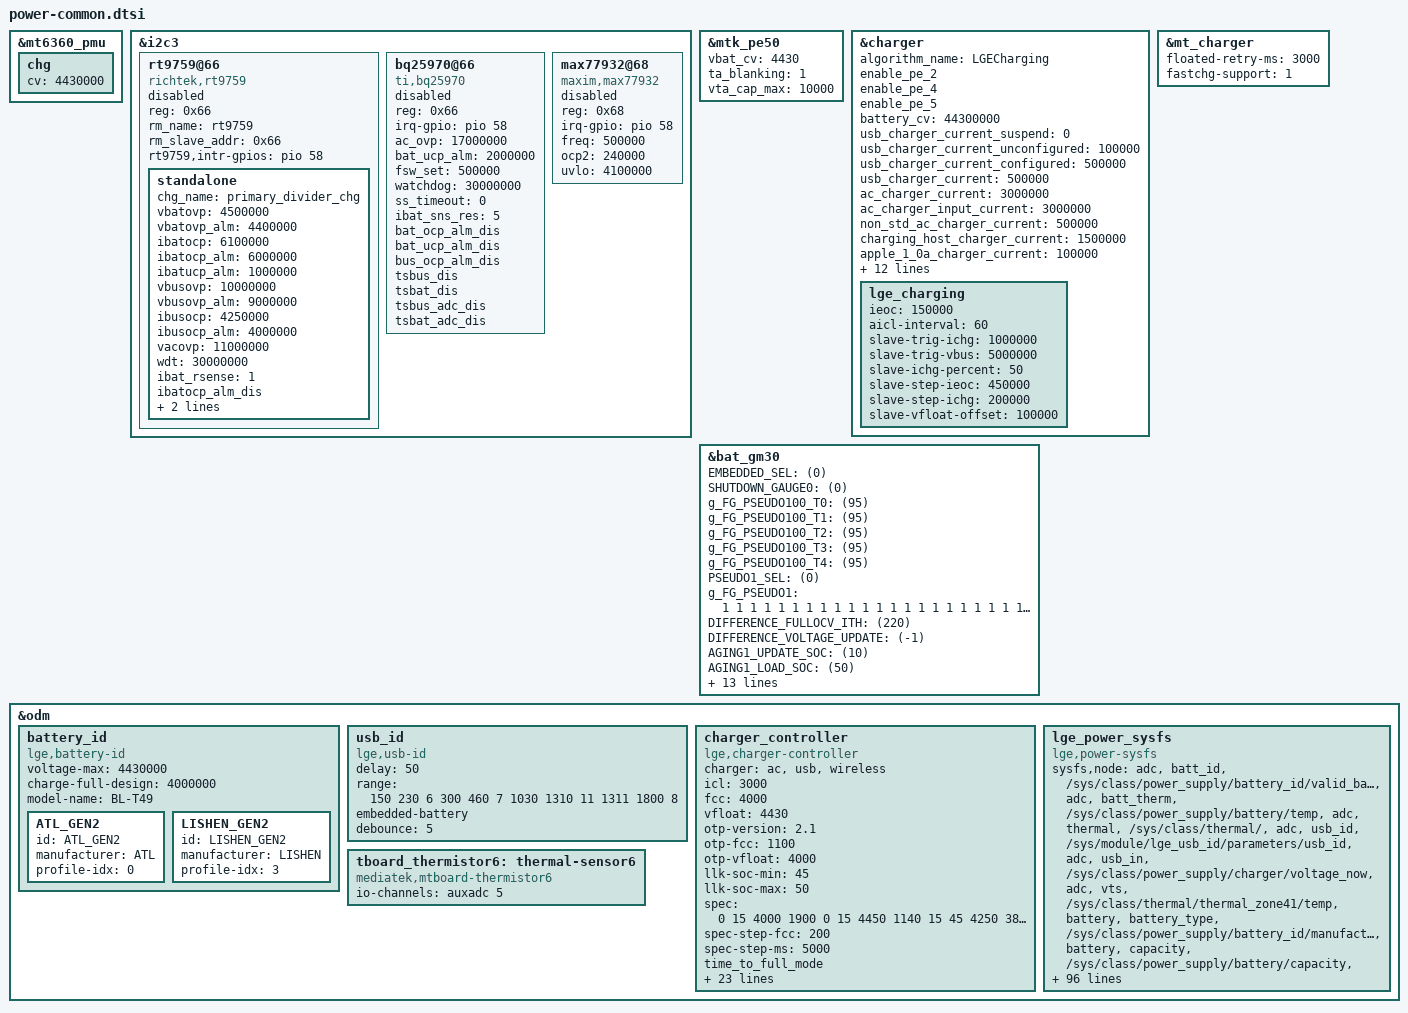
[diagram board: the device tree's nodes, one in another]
/*
 * Mediatek's mt6885 SoC device tree source
 *
 * Copyright (C) 2016 MediaTek Inc.
 *
 * This program is free software; you can redistribute it and/or modify
 * it under the terms of the GNU General Public License version 2 as
 * published by the Free Software Foundation.
 *
 * This program is distributed in the hope that it will be useful,
 * but WITHOUT ANY WARRANTY; without even the implied warranty of
 * MERCHANTABILITY or FITNESS FOR A PARTICULAR PURPOSE.
 * See http://www.gnu.org/licenses/gpl-2.0.html for more details.
 */

&mt6360_pmu {
	chg {
		cv = <4430000>;		/* uA */
	};
};

/* Cap Divider Charger */
&i2c3 {
	rt9759@66 {
		compatible = "richtek,rt9759";
		status = "disabled";
		reg = <0x66>;
		rm_name = "rt9759";
		rm_slave_addr = /bits/ 8 <0x66>;
		rt9759,intr-gpios = <&pio 58 0x0>;
		standalone {
			chg_name = "primary_divider_chg";
			vbatovp = <4500000>;
			vbatovp_alm = <4400000>;
			ibatocp = <6100000>;
			ibatocp_alm = <6000000>;
			ibatucp_alm = <1000000>;
			vbusovp = <10000000>;
			vbusovp_alm = <9000000>;
			ibusocp = <4250000>;
			ibusocp_alm = <4000000>;
			vacovp = <11000000>;
			wdt = <30000000>;
			ibat_rsense = <1>; /* 0: 2mohm, 1: 5mohm */
			ibatocp_alm_dis;
			ibatucp_alm_dis;
			ibusocp_alm_dis;
		};
	};
};

&i2c3 {
	bq25970@66 {
		compatible = "ti,bq25970";
		status = "disabled";
		reg = <0x66>;
		irq-gpio = <&pio 58 0x0>;
		ac_ovp = <17000000>;		/* 17 V */
		bat_ucp_alm = <2000000>;	/* 2 A */
		fsw_set = <500000>;		/* 500 kHz */
		watchdog = <30000000>;		/* 30 sec */
		ss_timeout = <0>;		/* disable */
		ibat_sns_res = <5>;		/* 5 ohm */
		bat_ocp_alm_dis;
		bat_ucp_alm_dis;
		bus_ocp_alm_dis;
		tsbus_dis;
		tsbat_dis;
		tsbus_adc_dis;
		tsbat_adc_dis;
	};
};

&i2c3 {
	max77932@68 {
		compatible = "maxim,max77932";
		status = "disabled";
		reg = <0x68>;
		irq-gpio = <&pio 58 0x0>;

		freq = <500000>;
		ocp2 = <240000>;
		uvlo = <4100000>;
	};
};

&mtk_pe50 {
	vbat_cv = <4430>;
	ta_blanking = <1>;
	vta_cap_max = <10000>;
};

&charger {
	algorithm_name = "LGECharging";
	enable_pe_2;
	enable_pe_4;
	enable_pe_5;

	/* common */
	battery_cv = <44300000>;

	/* charging current */
	usb_charger_current_suspend = <0>;
	usb_charger_current_unconfigured = <100000>;
	usb_charger_current_configured = <500000>;
	usb_charger_current = <500000>;
	ac_charger_current = <3000000>;
	ac_charger_input_current = <3000000>;
	non_std_ac_charger_current = <500000>;
	charging_host_charger_current = <1500000>;
	apple_1_0a_charger_current = <100000>;
	apple_2_1a_charger_current = <2100000>;
	ta_ac_charger_current = <3200000>;
	ta_ac_charger_input_current = <1800000>;
	pd_charger_current = <4000000>;

	/* PE 2.0 */
	pe20_ichg_level_threshold = <500000>; /* uA */
	ta_start_battery_soc = <0>;
	ta_stop_battery_soc = <97>;

	/* cable measurement impedance */
	vbat_cable_imp_threshold = <3000000>; /* uV */

	/* PD */
	pd_vbus_low_bound = <5000000>;
	pd_vbus_upper_bound = <9000000>;
	pd_ichg_level_threshold = <1000000>; /* uA */
	pd_stop_battery_soc = <80>;

	/* LGE Charging Algorithm */
	lge_charging {
		ieoc = <150000>;
		aicl-interval = <60>;

		/* slave charger */
		slave-trig-ichg = <1000000>;
		slave-trig-vbus = <5000000>;
		slave-ichg-percent = <50>;
		slave-step-ieoc = <450000>;
		slave-step-ichg = <200000>;
		slave-vfloat-offset = <100000>;
	};
};

&mt_charger {
	floated-retry-ms = <3000>; /* 3000 ms */
	fastchg-support = <1>;
};

&bat_gm30 {
	/*	Configures whether using embedded battery or not.*/
	EMBEDDED_SEL = <(0)>;
	/* SOC_ZERO_PERCENT shutdown_cond  1:enable , 0:disable */
	SHUTDOWN_GAUGE0 = <(0)>;

	/*      Pseudo 100% percentage at T0.*/
	g_FG_PSEUDO100_T0 = <(95)>;
	/*      Pseudo 100% percentage at T1.*/
	g_FG_PSEUDO100_T1 = <(95)>;
	/*      Pseudo 100% percentage at T2.*/
	g_FG_PSEUDO100_T2 = <(95)>;
	/*      Pseudo 100% percentage at T3.*/
	g_FG_PSEUDO100_T3 = <(95)>;
	/*      Pseudo 100% percentage at T4.*/
	g_FG_PSEUDO100_T4 = <(95)>;

	PSEUDO1_SEL = <(0)>;

	g_FG_PSEUDO1 = <1  1  1  1
			1  1  1  1
			1  1  1  1
			1  1  1  1
			1  1  1  1
			1  1  1  1
			1  1  1  1
			1  1  1  1
			1  1  1  1
			1  1  1  1>;

	DIFFERENCE_FULLOCV_ITH = <(220)>;
	DIFFERENCE_VOLTAGE_UPDATE = <(-1)>;
	AGING1_UPDATE_SOC = <(10)>;
	AGING1_LOAD_SOC = <(50)>;
	AGING_TEMP_DIFF = <(15)>;
	AGING_TEMP_LOW_LIMIT = <(15)>;
	AGING_TEMP_HIGH_LIMIT = <(45)>;
	ZCV_SUSPEND_TIME = <(9)>;
	SLEEP_CURRENT_AVG = <(500)>; /*0.1mA*/

	CAR_TUNE_VALUE = <(100)>;
	HWOCV_OLDOCV_DIFF_CHR = <(2000)>;
	SWOCV_OLDOCV_DIFF_CHR = <(2000)>;
	VIR_OLDOCV_DIFF_EMB = <(2000)>;
	VIR_OLDOCV_DIFF_EMB_LT = <(2000)>;

	POWER_ON_CAR_CHR = <(20)>;
	POWER_ON_CAR_NOCHR = <(-35)>;

	/*The ui_soc will keep 100% until SOC drop X percents after unplugged.*/
	KEEP_100_PERCENT = <(3)>;

#include <lge/battery_BL-T49.dtsi>
};

/* Battery ID */
&odm {
	battery_id {
		compatible = "lge,battery-id";

		voltage-max = <4430000>;
		charge-full-design = <4000000>;
		model-name = "BL-T49";

		ATL_GEN2 {
			id = "ATL_GEN2";
			manufacturer = "ATL";
			profile-idx = <0>;
		};
		LISHEN_GEN2 {
			id = "LISHEN_GEN2";
			manufacturer = "LISHEN";
			profile-idx = <3>;
		};
	};
};

/* USB ID */
&odm {
	usb_id {
		compatible = "lge,usb-id";

		delay = <50>;

		/*
		 * Pull-up : 1.8V 500k (20%)
		 * ID : 56k (20%), 130k (20%), 910k (20%)
		 */
		range = <
		/*	min 	max 	type	*/
			150	230	6	/* 6: LT_CABLE_56K */
			300	460	7	/* 7: LT_CABLE_130K */
			1030	1310	11	/* 11: LT_CABLE_910K */
			1311	1800	8	/* 8: USB_CABLE_400MA */
		>;

		embedded-battery;
		debounce = <5>;
	};
};

/* Charger Controller */
&odm {
	charger_controller {
		compatible = "lge,charger-controller";
		charger = "ac", "usb", "wireless";

		/* base information */
		icl = <3000>;
		fcc = <4000>;
		vfloat = <4430>;

		/* otp */
		otp-version = "2.1";
		otp-fcc = <1100>;
		otp-vfloat = <4000>;

		/* llk */
		llk-soc-min = <45>;
		llk-soc-max = <50>;

		/* spec */
		spec = <
			 0 15 4000 1900	/* 0.5C */
			 0 15 4450 1140	/* 0.3C */
			15 45 4250 3880	/* 1.0C */
			15 45 4450 2328	/* 0.6C */
			45 60 4410 1900	/* 0.5C */
		>;
		spec-step-fcc = <200>;
		spec-step-ms = <5000>;

		/* time to full */
		time_to_full_mode;
		battery_full_capacity = <4000>;
		sdp_current = <500>;
		dcp_current = <2000>;
		pep_current = <2800>;
		non_std_current = <500>;
		report_ttf_comp = <0>;
		sdp_comp = <3>;
		dcp_comp = <15>;
		cdp_comp = <15>;
		pep_comp = <2>;
		pd_comp = <2>;
		non_std_comp = <3>;
		min_comp = <0>;
		batt_comp = <
			0	/* LGC */
			0	/* TOCAD */
			(-3)	/* ATL */
			0	/* BYD */
			0	/* LISHEN */
		>;
		cc_data = <
			/* current soc */
			2000	0
		>;
		cv_data = <
			/* current soc time */
			1892	811	2296
			1858	816	2262
			1810	821	2227
			1769	826	2192
			1733	831	2155
			1690	836	2121
			1656	841	2083
			1612	846	2045
			1576	851	2007
			1535	856	1966
			1491	861	1923
			1455	866	1880
			1413	871	1837
			1376	876	1794
			1334	881	1748
			1295	886	1700
			1253	891	1652
			1217	896	1603
			1175	901	1551
			1136	906	1492
			1095	911	1436
			1053	916	1379
			1020	921	1318
			977	926	1254
			938	931	1189
			900	936	1122
			861	941	1051
			825	946	978
			792	951	904
			753	956	825
			718	961	743
			689	966	660
			650	971	570
			621	976	475
			588	981	377
			551	988	241
			519	991	144
			494	994	39
			481	996	0
			479	1000	0
		>;

		/* game */
		game-fcc = <500>;

		game-light-fcc = <500>;
		game-light-load = <80>;
		game-light-sec = <100>;

		game-lowbatt-fcc = <500>;
		game-lowbatt-soc = <15>;
	};
};

/* Unified Power Sysfs */
&odm {
	lge_power_sysfs {
		compatible = "lge,power-sysfs";
		sysfs,node =
			/* adc group */
			"adc", "batt_id", "/sys/class/power_supply/battery_id/valid_batt_id",
			"adc", "batt_therm", "/sys/class/power_supply/battery/temp",
			"adc", "thermal", "/sys/class/thermal/",
			"adc", "usb_id", "/sys/module/lge_usb_id/parameters/usb_id",
			"adc", "usb_in", "/sys/class/power_supply/charger/voltage_now",
			"adc", "vts", "/sys/class/thermal/thermal_zone41/temp",
			/* battery group */
			"battery", "battery_type", "/sys/class/power_supply/battery_id/manufacturer",
			"battery", "capacity", "/sys/class/power_supply/battery/capacity",
			"battery", "cycle", "/sys/class/power_supply/battery/battery_cycle",
			"battery", "raw_capacity", "/sys/class/power_supply/battery/raw_capacity",
			"battery", "ttf_capacity", "/sys/class/power_supply/battery/ttf_capacity",
			"battery", "health", "/sys/class/power_supply/battery/health",
			"battery", "present", "/sys/class/power_supply/battery/present",
			"battery", "pseudo_batt", "/sys/module/pseudo_power_supply/parameters/pseudo_batt",
			"battery", "temp", "/sys/class/power_supply/battery/temp",
			"battery", "valid_batt_id", "/sys/class/power_supply/battery_id/valid_batt_id",
			"battery", "check_batt_id_for_aat", "/sys/class/power_supply/battery_id/check_batt_id_for_aat",
			"battery", "voltage_now", "/sys/class/power_supply/battery/voltage_now",
			"battery", "status", "/sys/class/power_supply/battery/status",
			"battery", "time_to_full_now", "/sys/module/charger_controller/parameters/ccd_ttf",
			"battery", "charge_full", "/sys/class/power_supply/battery/charge_full",
			"battery", "charge_full_design", "/sys/class/power_supply/battery/charge_full_design",
			"battery", "charge_counter", "/sys/class/power_supply/battery/charge_counter",
			"battery", "battery_age", "/sys/class/power_supply/battery/battery_age",
			"battery", "battery_age_level", "/sys/class/power_supply/battery/battery_age_level",
			"battery", "condition", "/sys/class/power_supply/battery/battery_condition",
			/* charger group */
			"charger", "ac_online", "/sys/class/power_supply/ac/online",
			"charger", "usb_online", "/sys/class/power_supply/usb/online",
			"charger", "wlc_online", "/sys/class/power_supply/wlc/online",
			"charger", "present", "/sys/class/power_supply/charger/online",
			"charger", "ibat_current", "/sys/class/power_supply/battery/current_now",
			"charger", "ichg_current", "/sys/class/power_supply/usb/current_max",
			"charger", "charging_enabled", "/sys/class/power_supply/charger_controller/charging_enabled",
			"charger", "restricted_charging", "/sys/module/charger_controller/parameters/restricted_charging",
			"charger", "store_demo_enabled", "/sys/class/power_supply/charger_controller/store_demo_enabled",
			"charger", "fastchg", "/sys/class/power_supply/charger/fastchg",
			"charger", "fastchg_support", "/sys/class/power_supply/charger/fastchg_support",
			"charger", "incompatible", "/sys/class/power_supply/charger/incompatible_chg",
			"charger", "pseudo_hvdcp", "/sys/module/pseudo_power_supply/parameters/hvdcp_mode",
			"charger", "chgstep", "/sys/module/charger_controller/parameters/chgstep",
			"charger", "chgtype", "/sys/module/charger_controller/parameters/chgtype",
			/* lcd group */
			"lcd", "brightness", "/sys/class/leds/lcd-backlight/brightness",
			"lcd", "max_brightness", "/sys/class/leds/lcd-backlight/max_brightness",
			/* key led group */
			/* cpu group */
			"cpu", "game_mode", "/proc/ppm/policy/auto_game_limit",
			/* gpu group */
			/* platform group */
			/* perf service feature group */
			/* testmode group */
			"testmode", "batt_id", "/sys/class/power_supply/battery_id/batt_id",
			"testmode", "battexist", "/sys/class/power_supply/battery/present",
			"testmode", "charge", "/sys/module/charger_controller/parameters/atcmd_charge",
			"testmode", "chcomp", "/sys/module/charger_controller/parameters/atcmd_chcomp",
			"testmode", "chgmodeoff", "/sys/module/charger_controller/parameters/atcmd_chgmodeoff",
			"testmode", "current_max", "/sys/class/power_supply/usb/current_max",
			"testmode", "current_now", "/sys/class/power_supply/battery/current_now",
			"testmode", "fuelval", "/sys/class/power_supply/battery/capacity",
			"testmode", "temp", "/sys/module/charger_controller/parameters/atcmd_batmp",
			"testmode", "usb_id", "/sys/module/lge_usb_id/parameters/atcmd_usb_id",
			"testmode", "valid_batt_id", "/sys/class/power_supply/battery_id/check_batt_id_for_aat",
			"testmode", "voltage_now", "/sys/class/power_supply/battery/voltage_now";
	};
};

&odm {
	tboard_thermistor6: thermal-sensor6 {
		compatible = "mediatek,mtboard-thermistor6";
		io-channels = <&auxadc 5>;
		io-channel-names = "thermistor-ch5";
	};
};
